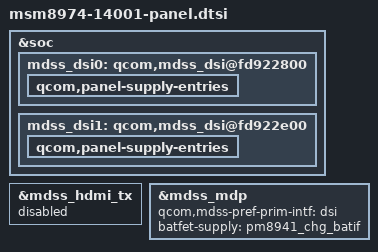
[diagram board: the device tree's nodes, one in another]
/* Copyright (c) 2012-2013, The Linux Foundation. All rights reserved.
 * Copyright (c) 2013-2014 OPPO Mobile communication Corp.ltd.
 * Copyright (c) 2014, The CyanogenMod Project
 *
 * This program is free software; you can redistribute it and/or modify
 * it under the terms of the GNU General Public License version 2 and
 * only version 2 as published by the Free Software Foundation.
 *
 * This program is distributed in the hope that it will be useful,
 * but WITHOUT ANY WARRANTY; without even the implied warranty of
 * MERCHANTABILITY or FITNESS FOR A PARTICULAR PURPOSE.  See the
 * GNU General Public License for more details.
 */

/include/ "dsi-panel-jdi-1080p-cmd.dtsi"
/include/ "dsi-panel-sharp-1080p-cmd.dtsi"
/include/ "dsi-panel-truly-1080p-cmd.dtsi"

&soc {
	mdss_dsi0: qcom,mdss_dsi@fd922800 {
		qcom,panel-supply-entries {
			/delete-property/ qcom,panel-supply-entry@0;
		};
	};

	mdss_dsi1: qcom,mdss_dsi@fd922e00 {
		qcom,panel-supply-entries {
			/delete-property/ qcom,panel-supply-entry@0;
		};
	};
};

&mdss_hdmi_tx {
	status = "disabled";
};

&mdss_mdp {
	qcom,mdss-pref-prim-intf = "dsi";
	batfet-supply = <&pm8941_chg_batif>;
};
